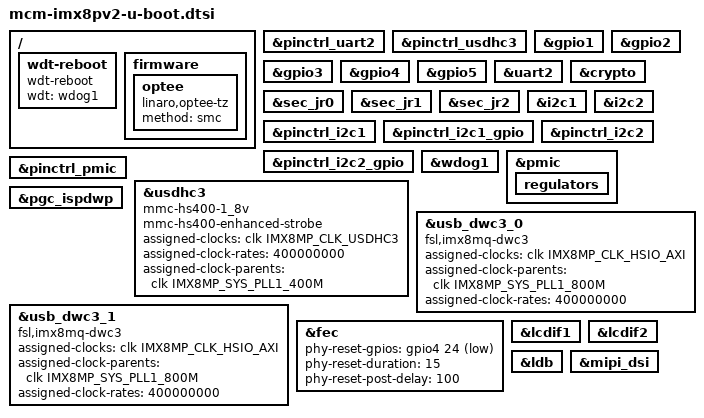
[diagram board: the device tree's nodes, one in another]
// SPDX-License-Identifier: GPL-2.0+
/*
 * Copyright 2026 CompuLab
 */

#include "imx8mp-u-boot.dtsi"
/delete-node/ &binman;
#include "compulab-imx8mp-binman.dtsi"

/ {
	wdt-reboot {
		compatible = "wdt-reboot";
		wdt = <&wdog1>;
		bootph-pre-ram;
	};

	firmware {
		optee {
			compatible = "linaro,optee-tz";
			method = "smc";
		};
	};
};

&pinctrl_uart2 {
	bootph-pre-ram;
};

&pinctrl_usdhc3 {
	bootph-pre-ram;
};

&gpio1 {
	bootph-pre-ram;
};

&gpio2 {
	bootph-pre-ram;
};

&gpio3 {
	bootph-pre-ram;
};

&gpio4 {
	bootph-pre-ram;
};

&gpio5 {
	bootph-pre-ram;
};

&uart2 {
	bootph-pre-ram;
};

&crypto {
	bootph-pre-ram;
};

&sec_jr0 {
	bootph-pre-ram;
};

&sec_jr1 {
	bootph-pre-ram;
};

&sec_jr2 {
	bootph-pre-ram;
};

&i2c1 {
	bootph-pre-ram;
};

&i2c2 {
	bootph-pre-ram;
};

&pinctrl_i2c1 {
	bootph-pre-ram;
};

&pinctrl_i2c1_gpio {
	bootph-pre-ram;
};

&pinctrl_i2c2 {
	bootph-pre-ram;
};

&pinctrl_i2c2_gpio {
	bootph-pre-ram;
};

&wdog1 {
	bootph-pre-ram;
};

&pmic {
	bootph-pre-ram;
};

&pinctrl_pmic {
	bootph-pre-ram;
};

&pmic {
	regulators {
		bootph-pre-ram;
	};
};

&usdhc3 {
	bootph-pre-ram;
	mmc-hs400-1_8v;
	mmc-hs400-enhanced-strobe;
	assigned-clocks = <&clk IMX8MP_CLK_USDHC3>;
	assigned-clock-rates = <400000000>;
	assigned-clock-parents = <&clk IMX8MP_SYS_PLL1_400M>;
};

&pgc_ispdwp {
	/delete-property/ clocks;
};

&usb_dwc3_0 {
	compatible = "fsl,imx8mq-dwc3", "snps,dwc3";
	assigned-clocks = <&clk IMX8MP_CLK_HSIO_AXI>;
	assigned-clock-parents = <&clk IMX8MP_SYS_PLL1_800M>;
	assigned-clock-rates = <400000000>;
};

&usb_dwc3_1 {
	compatible = "fsl,imx8mq-dwc3", "snps,dwc3";
	assigned-clocks = <&clk IMX8MP_CLK_HSIO_AXI>;
	assigned-clock-parents = <&clk IMX8MP_SYS_PLL1_800M>;
	assigned-clock-rates = <400000000>;
};

/* Clock parents are configured by the U-Boot display/EQOS drivers. */

/* This FEC driver reads reset properties from the MAC node. */
&fec {
	phy-reset-gpios = <&gpio4 24 GPIO_ACTIVE_LOW>;
	phy-reset-duration = <15>;
	phy-reset-post-delay = <100>;
};

&lcdif1 {
	/delete-property/ assigned-clocks;
	/delete-property/ assigned-clock-parents;
	/delete-property/ assigned-clock-rates;
};

&lcdif2 {
	/delete-property/ assigned-clocks;
	/delete-property/ assigned-clock-parents;
	/delete-property/ assigned-clock-rates;
};

&ldb {
	/delete-property/ assigned-clocks;
	/delete-property/ assigned-clock-parents;
	/delete-property/ assigned-clock-rates;
};

&mipi_dsi {
	/delete-property/ assigned-clocks;
	/delete-property/ assigned-clock-parents;
	/delete-property/ assigned-clock-rates;
};
